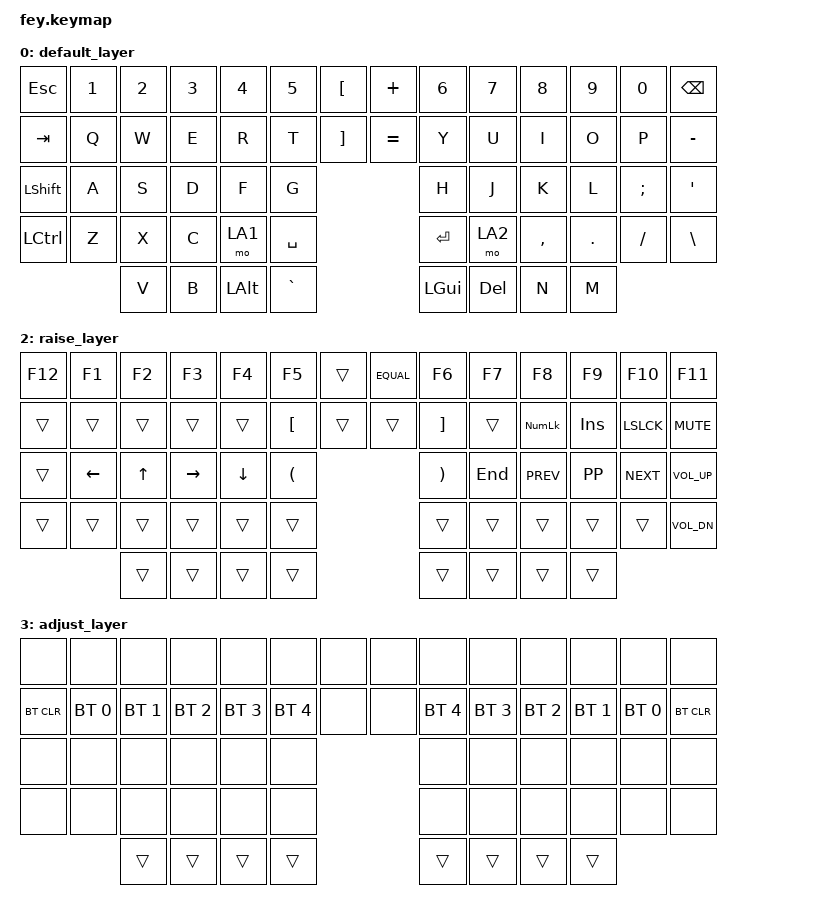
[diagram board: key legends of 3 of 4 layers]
/*
 * Copyright (c) 2020 The ZMK Contributors
 *
 * SPDX-License-Identifier: MIT
 */

#include <behaviors.dtsi>
#include <dt-bindings/zmk/keys.h>
#include <dt-bindings/zmk/bt.h>

#define DEF 0
#define LA1 1
#define LA2 2
#define LA3 3

/ {
        keymap {
                compatible = "zmk,keymap";

                default_layer {
// --------------------------------------------------------------------------------------------
// | ESC  |  1  |  2  |  3  |  4  |  5  |  [/{  |   |  +  |  6  |  7   |  8  |  9  |  0  | BACK |
// | TAB  |  Q  |  W  |  E  |  R  |  T  |  ]/}  |   | +/= |  Y  |  U   |  I  |  O  |  P  | -/_  |
// | SHFT |  A  |  S  |  D  |  F  |  G  |                 |  H  |  J   |  K  |  L  | ;/: | '/"  |
// | LCTRL|  Z  |  X  |  C  | LA1 | SAP |                 | RET | LA2  | ,/< | ./> | //? | \/|  |
//              |  V  |  B  | LALT| `/~ |                 | LGUI| DEL   |  N  |  M  |
                        bindings = <
   &kp ESC   &kp N1 &kp N2 &kp N3 &kp N4   &kp N5 &kp LBKT     &kp PLUS  &kp N6    &kp N7  &kp N8    &kp N9   &kp N0   &kp BSPC
   &kp TAB   &kp Q  &kp W  &kp E  &kp R    &kp T  &kp RBKT     &kp EQUAL &kp Y     &kp U   &kp I     &kp O    &kp P    &kp MINUS
   &kp LSHFT &kp A  &kp S  &kp D  &kp F    &kp G                         &kp H     &kp J   &kp K     &kp L    &kp SEMI &kp SQT
   &kp LCTRL &kp Z  &kp X  &kp C  &mo LA1  &kp SPACE                     &kp ENTER &mo LA2 &kp COMMA &kp DOT  &kp FSLH &kp BSLH
                    &kp V  &kp B  &kp LALT &kp GRAVE                     &kp LGUI  &kp DEL &kp N &kp M
                        >;
                };
                lower_layer {
// --------------------------------------------------------------------------------------------
// |  ~   |  !  |  @  |  #  |  $  |  %  |     |   |     |  ^  |  &   |  *  |  (  |  )  |  DEL |
// |      |     |     |     |     | [/{ |PSCRN|   |     | ]/} |  7   |  8  |  9  |     |   +  |
// |      | HOME|PG_UP|PG_DN| END |  (  |               |  )  |  4   |  5  |  6  | -/_ |   |  |
// |      |     |     |     |     |     |               |     |  1   |  2  |  3  | =/+ |   -  |
//              |     |     |     |     |               |     |      |     |  0  |
                        bindings = <
   &kp TILDE  &kp EXCL  &kp AT    &HASH     &DLLR   &kp PRCNT &trans     &trans   &CARET   &kp AMPS  &kp ASTRK  &kp LPAR  &kp RPAR  &kp DEL
   &trans     &trans    &trans    &trans    &trans  &kp LBKT  &kp PSCRN  &trans   &RBKT    &kp KP_N7 &kp KP_N8  &kp KP_N9 &trans    &kp PLUS 
   &trans     &kp HOME  &kp PG_UP &kp PG_DN &kp END &kp LPAR                      &RPAR    &kp KP_N4 &kp KP_N5  &kp KP_N6 &kp MINUS &kp PIPE 
   &trans     &trans    &trans    &trans    &trans  &trans                        &trans   &kp KP_N1 &kp KP_N2  &kp KP_N3 &kp EQUAL &kp KP_MINUS 
              &trans    &trans    &trans    &trans  &trans                        &trans   &trans    &trans     &kp KP_N0
                        >;
                };

                raise_layer {
// --------------------------------------------------------------------------------------------
// | F12 |  F1 |  F2 |  F3 | F4  |  F5 |     |   | =/+ | F6  |  F7  |  F8 |  F9 | F10 | F11  |
// |     |     |     |     |     | [/{ |     |   |     | ]/} |      |KP_NUM|INSERT|LSLCK|K_MUTE|
// |     | LEFT|  UP |RIGHT| DOWN|  (  |               |  )  | END  |K_PREV| K_PP|K_NEXT|K_VOL_UP|
// |     |     |     |     |     |     |               |     |      |     |     |     |K_VOL_DN|
//             |     |     |     |     |               |     |      |     |     |
                        bindings = <
   &kp F12 &kp F1   &kp F2 &kp F3    &kp F4   &kp F5   &trans   &EQUAL  &kp F6   &kp F7  &kp F8     &kp F9     &kp F10    &kp F11
   &trans  &trans   &trans &trans    &trans   &kp LBKT &trans   &trans  &kp RBKT &trans  &kp KP_NUM &kp INSERT &kp LSLCK  &kp K_MUTE
   &trans  &kp LEFT &kp UP &kp RIGHT &kp DOWN &kp LPAR                  &kp RPAR &kp END &kp K_PREV &kp K_PP   &kp K_NEXT &kp K_VOL_UP
   &trans  &trans   &trans &trans    &trans   &trans                    &trans   &trans  &trans     &trans     &trans     &kp K_VOL_DN
                    &trans &trans    &trans   &trans                    &trans   &trans  &trans     &trans
                        >;
                };
                   adjust_layer {
// --------------------------------------------------------------------------------------------
// | BLDR |     |     |     |     |     |     |   |     |     |      |     |     |     | BLDR |
// | BCTRL| BT0 | BT1 | BT2 | BT3 | BT4 |     |   |     | BT4 | BT3  | BT2 | BT1 | BT0 | BTCLR|
// |      |     |     |     |     |     |               |     |      |     |     |     |      |
// |      |     |     |     |     |     |               |     |      |     |     |     |      |
//              |     |     |     |     |               |     |      |     |     |
                        bindings = <
   &none       &none        &none        &none        &none        &none        &none          &none    &none        &none        &none        &none        &none         &none
   &bt BT_CLR  &bt BT_SEL 0 &bt BT_SEL 1 &bt BT_SEL 2 &bt BT_SEL 3 &bt BT_SEL 4 &none          &none    &bt BT_SEL 4 &bt BT_SEL 3 &bt BT_SEL 2 &bt BT_SEL 1 &bt BT_SEL 0  &bt BT_CLR
   &none       &none        &none        &none        &none        &none                                &none        &none        &none        &none        &none         &none
   &none       &none        &none        &none        &none        &none                                &none        &none        &none        &none        &none         &none
                            &trans       &trans       &trans       &trans                               &trans       &trans       &trans       &trans
                        >;
                };
        };
};
